# haltium_celldsp register map
Vendor: Nordic Semiconductor; Series: nRFHaltium; File version: 1
Registers are 32-bit, read-write, reset 0x0 unless marked. A register's access mark holds for its fields unless they carry their own. Offsets are from the block's base; [hi:lo] are bit positions; lines under a group give offsets from that group; {n}, {i} and the like mark numbered series; 'fields as' and 'values as' point back to an identical list.

## PCGCS0 — PCGCSlave
Base 0x45022000
0x78 TRIGZEROPENALTY ro — Trigger zero penalty
  [0] TRIGGER
    1=Enable (Trigger zero penalty)
0x7C TRIGFULLPENALTY ro — Trigger full penalty
  [0] TRIGGER
    1=Enable (Trigger full penalty)
{0xC00+4i} PENALTY[{i}] (i=0..1) ro — Description collection: Penalty level for power/clock pair n
  [7:0] PENALTY — Penalty level
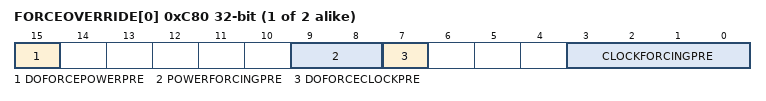
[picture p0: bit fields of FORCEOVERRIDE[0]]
{0xC80+4i} FORCEOVERRIDE[{i}] (i=0..1) ro — Description collection: Force override of power/clock pair n
  [15] DOFORCEPOWERPRE, [9:8] POWERFORCINGPRE, [7] DOFORCECLOCKPRE, [3:0] CLOCKFORCINGPRE

## TRACEDELAYREG — Trace delay register
Base 0x45027000
0x504 DELAYREGCONFIG — Configuration register for DELAYREG delay
  [4:0] DELAYREGCONFIG — Register write delay, configurable between 0 and 31 clock cycles. Delay between apbPEnable and apbPReady is adjusted to the configured value, except for the small values, when minimum interconnect delay exist.
0x600 DELAYREG wo — Dummy register with adjustable write delay. Occupies 0x100 address range i.e. 256bytes. This space emulates the extended stimulus port area of ARM Coresight STM.
  [31:0] DELAYREG — Dummy register with adjustable write delay

## BELLBOARD — BELLBOARD APB registers
Base 0x4F09D000
{0x0+4i} TASKS_TRIGGER[{i}] (i=0..31) wo — Description collection: Task TRIGGER[n]
  [0] TASKS_TRIGGER — Task TRIGGER[n]
    1=Trigger task
{0x100+4i} EVENTS_TRIGGERED[{i}] (i=0..31) — Description collection: Event TRIGGERED[n]
  [0] EVENTS_TRIGGERED — Event TRIGGERED[n]
    0=NotGenerated (Event not generated); 1=Generated (Event generated)
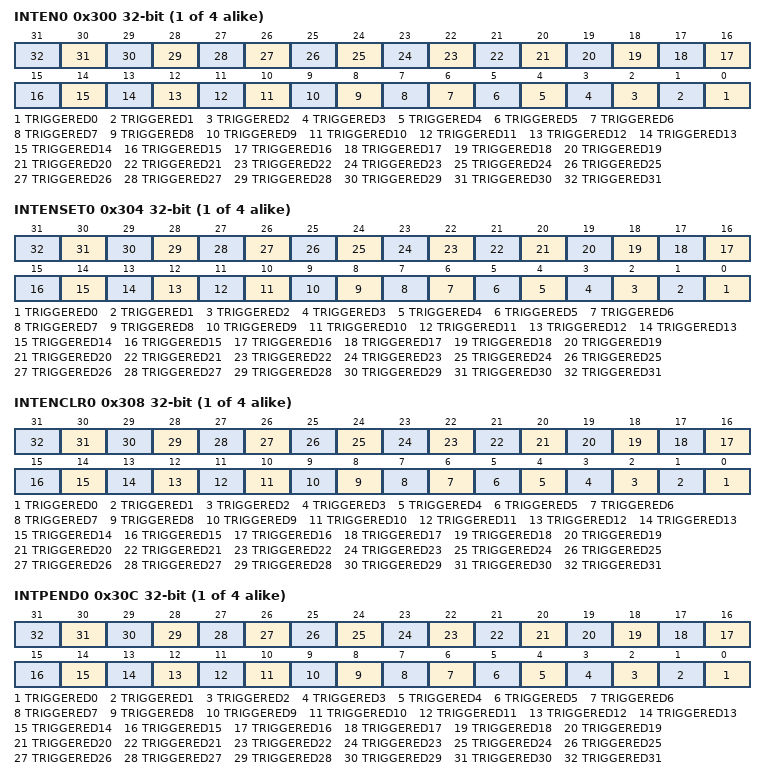
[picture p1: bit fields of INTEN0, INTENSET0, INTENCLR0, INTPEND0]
{0x300+0x10*i} INTEN{i} (i=0..3) — Enable or disable interrupt
  [all] fields
    0=Disabled; 1=Enabled
  [n] TRIGGERED{n} (n=0..31) — Enable or disable interrupt for event TRIGGERED[{n}]
{0x304+0x10*i} INTENSET{i} (i=0..3) — Enable interrupt
  [all] fields
    on read: 0=Disabled (Read: Disabled); 1=Enabled (Read: Enabled) | on write: 1=Set (Enable)
  [n] TRIGGERED{n} (n=0..31) — Write '1' to enable interrupt for event TRIGGERED[{n}]
{0x308+0x10*i} INTENCLR{i} (i=0..3) — Disable interrupt
  [all] fields
    on read: 0=Disabled (Read: Disabled); 1=Enabled (Read: Enabled) | on write: 1=Clear (Disable)
  [n] TRIGGERED{n} (n=0..31) — Write '1' to disable interrupt for event TRIGGERED[{n}]
{0x30C+0x10*i} INTPEND{i} ro (i=0..3) — Pending interrupts
  [all] fields
    on read: 0=NotPending (Read: Not pending); 1=Pending (Read: Pending)
  [n] TRIGGERED{n} (n=0..31) — Read pending status of interrupt for event TRIGGERED[{n}]

## GLOBAL_IPCT120 — IPCT APB registers 0
Base 0x4F8D1000
Same registers: GLOBAL_IPCT130 0x4F921000
{0x0+4i} TASKS_SEND[{i}] (i=0..7) wo — Description collection: Trigger event on IPCT source channel n
  [0] TASKS_SEND — Trigger event on IPCT source channel n
    1=Trigger task
{0x40+4i} TASKS_ACK[{i}] (i=0..7) wo — Description collection: Acknowledge RECEIVE event on IPCT sink channel n
  [0] TASKS_ACK — Acknowledge RECEIVE event on IPCT sink channel n
    1=Trigger task
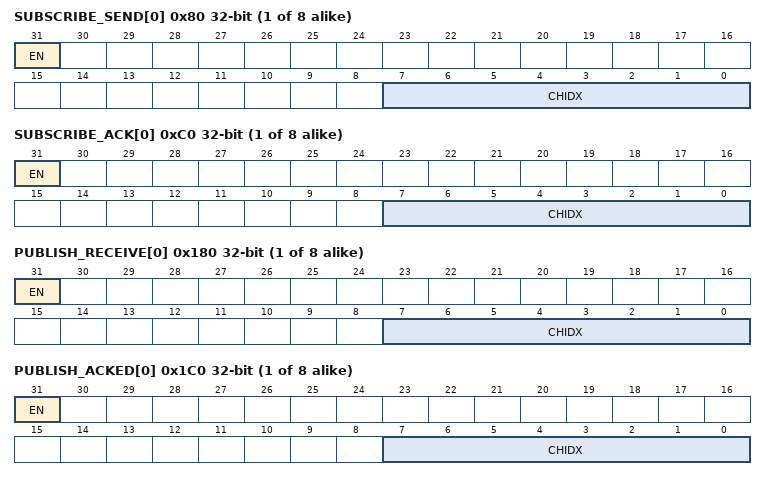
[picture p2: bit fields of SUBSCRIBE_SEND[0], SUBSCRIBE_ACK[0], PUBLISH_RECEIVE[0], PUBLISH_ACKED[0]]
{0x80+4i} SUBSCRIBE_SEND[{i}] (i=0..7) — Description collection: Subscribe configuration for task SEND[n]
  [31] EN
    0=Disabled (Disable subscription); 1=Enabled (Enable subscription)
  [7:0] CHIDX — DPPI channel that task SEND[n] will subscribe to
{0xC0+4i} SUBSCRIBE_ACK[{i}] (i=0..7) — Description collection: Subscribe configuration for task ACK[n]
  [31] EN
    values as SUBSCRIBE_SEND[0].EN
  [7:0] CHIDX — DPPI channel that task ACK[n] will subscribe to
{0x100+4i} EVENTS_RECEIVE[{i}] (i=0..7) — Description collection: Event received on IPCT sink channel n
  [0] EVENTS_RECEIVE — Event received on IPCT sink channel n
    0=NotGenerated (Event not generated); 1=Generated (Event generated)
{0x140+4i} EVENTS_ACKED[{i}] (i=0..7) — Description collection: SEND task on IPCT source channel n was acknowledged
  [0] EVENTS_ACKED — SEND task on IPCT source channel n was acknowledged
    values as EVENTS_RECEIVE[0].EVENTS_RECEIVE
{0x180+4i} PUBLISH_RECEIVE[{i}] (i=0..7) — Description collection: Publish configuration for event RECEIVE[n]
  [31] EN
    0=Disabled (Disable publishing); 1=Enabled (Enable publishing)
  [7:0] CHIDX — DPPI channel that event RECEIVE[n] will publish to
{0x1C0+4i} PUBLISH_ACKED[{i}] (i=0..7) — Description collection: Publish configuration for event ACKED[n]
  [31] EN
    values as PUBLISH_RECEIVE[0].EN
  [7:0] CHIDX — DPPI channel that event ACKED[n] will publish to
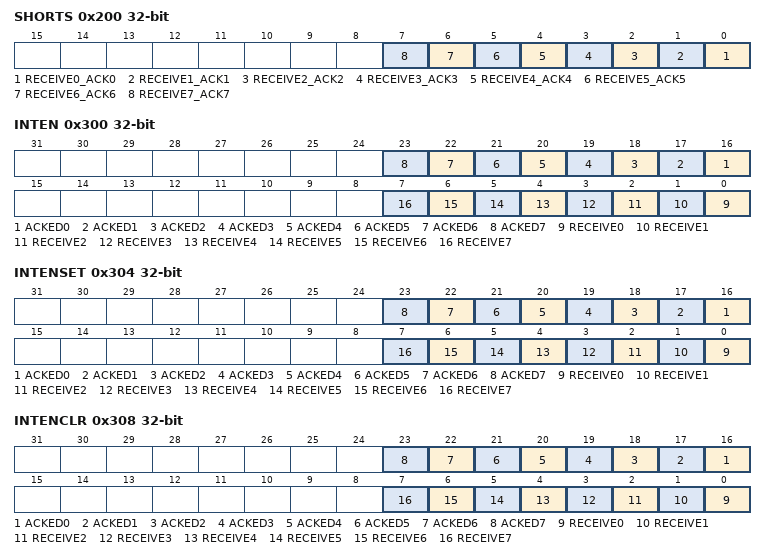
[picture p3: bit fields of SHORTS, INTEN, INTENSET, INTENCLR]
0x200 SHORTS — Shortcuts between local events and tasks
  [all] fields
    0=Disabled (Disable shortcut); 1=Enabled (Enable shortcut)
  [n] RECEIVE{n}_ACK{n} (n=0..7) — Shortcut between event RECEIVE[{n}] and task ACK[{n}]
0x300 INTEN — Enable or disable interrupt
  [all] fields
    0=Disabled; 1=Enabled
  [n+16] ACKED{n} (n=0..7) — Enable or disable interrupt for event ACKED[{n}]
  [n] RECEIVE{n} (n=0..7) — Enable or disable interrupt for event RECEIVE[{n}]
0x304 INTENSET — Enable interrupt
  [all] fields
    on read: 0=Disabled (Read: Disabled); 1=Enabled (Read: Enabled) | on write: 1=Set (Enable)
  [n+16] ACKED{n} (n=0..7) — Write '1' to enable interrupt for event ACKED[{n}]
  [n] RECEIVE{n} (n=0..7) — Write '1' to enable interrupt for event RECEIVE[{n}]
0x308 INTENCLR — Disable interrupt
  [all] fields
    on read: 0=Disabled (Read: Disabled); 1=Enabled (Read: Enabled) | on write: 1=Clear (Disable)
  [n+16] ACKED{n} (n=0..7) — Write '1' to disable interrupt for event ACKED[{n}]
  [n] RECEIVE{n} (n=0..7) — Write '1' to disable interrupt for event RECEIVE[{n}]
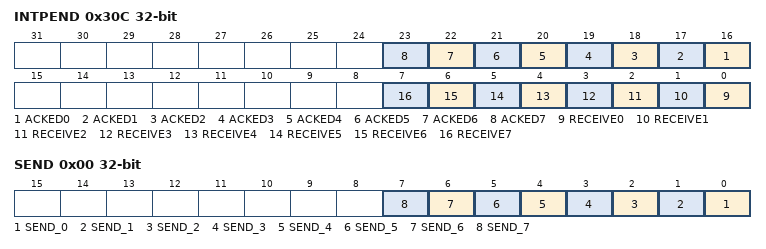
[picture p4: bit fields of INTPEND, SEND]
0x30C INTPEND ro — Pending interrupts
  [all] fields
    on read: 0=NotPending (Read: Not pending); 1=Pending (Read: Pending)
  [n+16] ACKED{n} (n=0..7) — Read pending status of interrupt for event ACKED[{n}]
  [n] RECEIVE{n} (n=0..7) — Read pending status of interrupt for event RECEIVE[{n}]
0x400 OVERFLOW group — Unspecified
  0x00 SEND — Overflow status for SEND tasks Write 0 to clear
    [all] fields
      1=Overflow (Task overflow has happened); 0=NoOverflow (Task overflow has not happened)
    [n] SEND_{n} (n=0..7) — Overflow status for SEND[{n}] task
